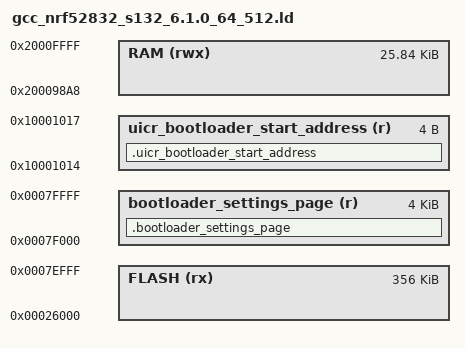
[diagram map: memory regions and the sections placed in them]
/* Linker script to configure memory regions. */

SEARCH_DIR(.)
GROUP(-lgcc -lc -lnosys)

MEMORY
{
  FLASH (rx) : ORIGIN = 0x0 + 152K, LENGTH = 512K - 152K - 4K /* 152 kB is taken by s132, 4 kB is taken by bootloader settings */
  RAM (rwx) :  ORIGIN = 0x200098a8, LENGTH = 0x6758 /* worst case taken from example apps. this can be significantly reduced if needed */
  bootloader_settings_page (r) : ORIGIN = 0x0 + 512K - 4K LENGTH = 4K
  uicr_bootloader_start_address (r) : ORIGIN = 0x10001014, LENGTH = 0x4
}

SECTIONS
{
  .bootloader_settings_page(NOLOAD) :
  {
    PROVIDE(__start_bootloader_settings_page = .);
    KEEP(*(SORT(.bootloader_settings_page*)))
    PROVIDE(__stop_bootloader_settings_page = .);
  } > bootloader_settings_page
  .uicr_bootloader_start_address :
  {
    PROVIDE(__start_uicr_bootloader_start_address = .);
    KEEP(*(SORT(.uicr_bootloader_start_address*)))
    PROVIDE(__stop_uicr_bootloader_start_address = .);
  } > uicr_bootloader_start_address
}

SECTIONS
{
  . = ALIGN(4);
  .mem_section_dummy_ram :
  {
  }
  .log_dynamic_data :
  {
    PROVIDE(__start_log_dynamic_data = .);
    KEEP(*(SORT(.log_dynamic_data*)))
    PROVIDE(__stop_log_dynamic_data = .);
  } > RAM
  .cli_sorted_cmd_ptrs :
  {
    PROVIDE(__start_cli_sorted_cmd_ptrs = .);
    KEEP(*(.cli_sorted_cmd_ptrs))
    PROVIDE(__stop_cli_sorted_cmd_ptrs = .);
  } > RAM
  .fs_data :
  {
    PROVIDE(__start_fs_data = .);
    KEEP(*(.fs_data))
    PROVIDE(__stop_fs_data = .);
  } > RAM

} INSERT AFTER .data;

SECTIONS
{
  .mem_section_dummy_rom :
  {
  }
  .sdh_soc_observers :
  {
    PROVIDE(__start_sdh_soc_observers = .);
    KEEP(*(SORT(.sdh_soc_observers*)))
    PROVIDE(__stop_sdh_soc_observers = .);
  } > FLASH
  .crypto_data :
  {
    PROVIDE(__start_crypto_data = .);
    KEEP(*(SORT(.crypto_data*)))
    PROVIDE(__stop_crypto_data = .);
  } > FLASH
  .log_const_data :
  {
    PROVIDE(__start_log_const_data = .);
    KEEP(*(SORT(.log_const_data*)))
    PROVIDE(__stop_log_const_data = .);
  } > FLASH
    .nrf_balloc :
  {
    PROVIDE(__start_nrf_balloc = .);
    KEEP(*(.nrf_balloc))
    PROVIDE(__stop_nrf_balloc = .);
  } > FLASH
    .nrf_queue :
  {
    PROVIDE(__start_nrf_queue = .);
    KEEP(*(.nrf_queue))
    PROVIDE(__stop_nrf_queue = .);
  } > FLASH
  .sdh_state_observers :
  {
    PROVIDE(__start_sdh_state_observers = .);
    KEEP(*(SORT(.sdh_state_observers*)))
    PROVIDE(__stop_sdh_state_observers = .);
  } > FLASH
  .sdh_stack_observers :
  {
    PROVIDE(__start_sdh_stack_observers = .);
    KEEP(*(SORT(.sdh_stack_observers*)))
    PROVIDE(__stop_sdh_stack_observers = .);
  } > FLASH
  .sdh_req_observers :
  {
    PROVIDE(__start_sdh_req_observers = .);
    KEEP(*(SORT(.sdh_req_observers*)))
    PROVIDE(__stop_sdh_req_observers = .);
  } > FLASH
    .cli_command :
  {
    PROVIDE(__start_cli_command = .);
    KEEP(*(.cli_command))
    PROVIDE(__stop_cli_command = .);
  } > FLASH
  .pwr_mgmt_data :
  {
    PROVIDE(__start_pwr_mgmt_data = .);
    KEEP(*(SORT(.pwr_mgmt_data*)))
    PROVIDE(__stop_pwr_mgmt_data = .);
  } > FLASH
  .sdh_ble_observers :
  {
    PROVIDE(__start_sdh_ble_observers = .);
    KEEP(*(SORT(.sdh_ble_observers*)))
    PROVIDE(__stop_sdh_ble_observers = .);
  } > FLASH
  .dfu_trans :
  {
    PROVIDE(__start_dfu_trans = .);
    KEEP(*(SORT(.dfu_trans*)))
    PROVIDE(__stop_dfu_trans = .);
  } > FLASH

} INSERT AFTER .text

INCLUDE "nrf_common.ld"
